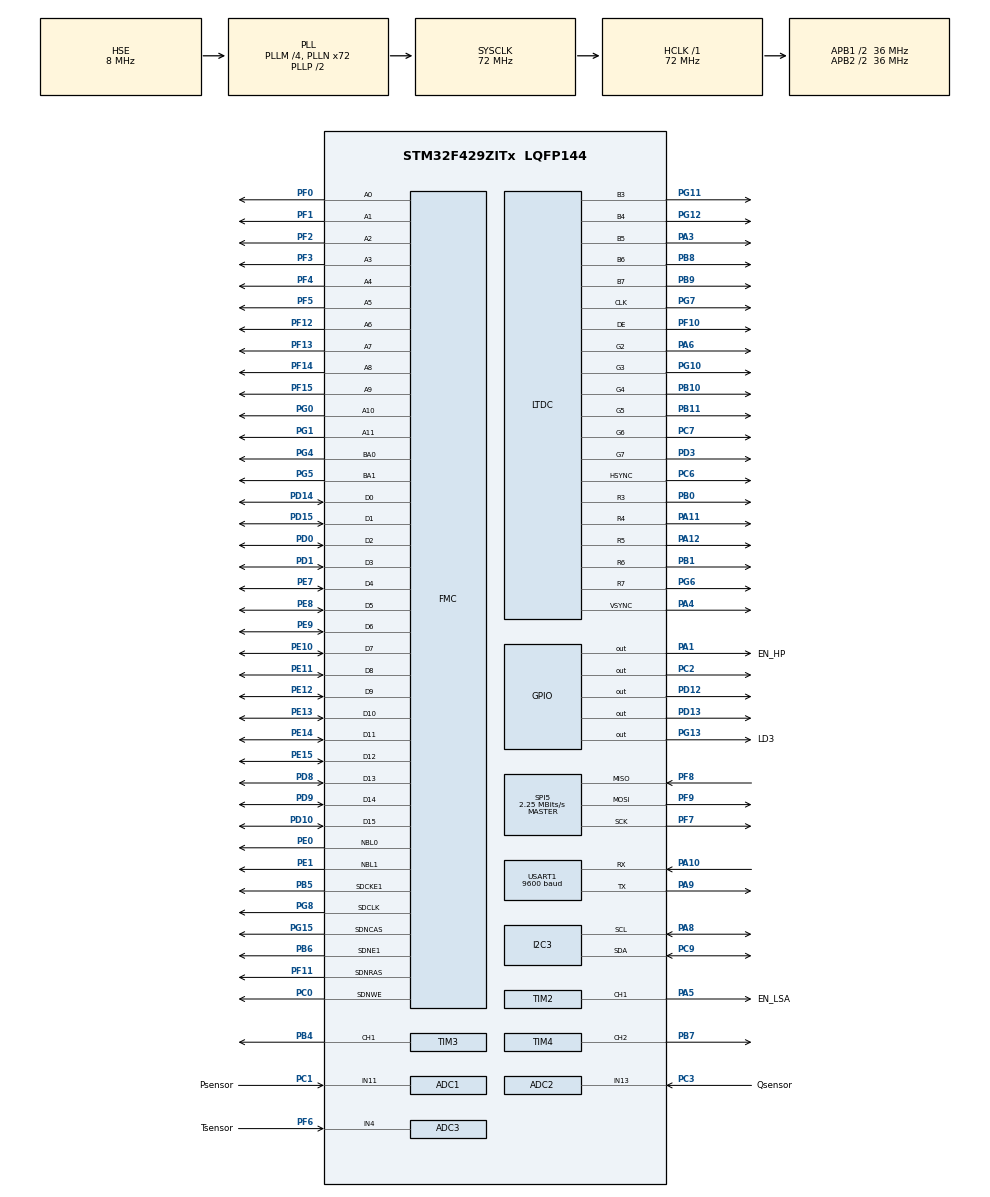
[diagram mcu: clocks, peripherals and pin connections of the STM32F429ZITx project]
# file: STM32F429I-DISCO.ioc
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ADC1.Channel-0\#ChannelRegularConversion=ADC_CHANNEL_11
ADC1.DMAContinuousRequests=ENABLE
ADC1.ExternalTrigConv=ADC_EXTERNALTRIGCONV_T3_TRGO
ADC1.ExternalTrigConvEdge=ADC_EXTERNALTRIGCONVEDGE_RISINGFALLING
ADC1.NbrOfConversionFlag=1
ADC1.Rank-0\#ChannelRegularConversion=1
ADC1.SamplingTime-0\#ChannelRegularConversion=ADC_SAMPLETIME_3CYCLES
ADC1.master=1
ADC2.Channel-0\#ChannelRegularConversion=ADC_CHANNEL_13
ADC2.DMAContinuousRequests=ENABLE
ADC2.ExternalTrigConv=ADC_EXTERNALTRIGCONV_T3_TRGO
ADC2.ExternalTrigConvEdge=ADC_EXTERNALTRIGCONVEDGE_RISINGFALLING
ADC2.NbrOfConversionFlag=1
ADC2.Rank-0\#ChannelRegularConversion=1
ADC2.SamplingTime-0\#ChannelRegularConversion=ADC_SAMPLETIME_3CYCLES
ADC3.Channel-0\#ChannelRegularConversion=ADC_CHANNEL_4
ADC3.ContinuousConvMode=ENABLE
ADC3.ExternalTrigConv=ADC_EXTERNALTRIGCONV_T3_TRGO
ADC3.ExternalTrigConvEdge=ADC_EXTERNALTRIGCONVEDGE_RISINGFALLING
ADC3.NbrOfConversionFlag=1
ADC3.Rank-0\#ChannelRegularConversion=1
ADC3.SamplingTime-0\#ChannelRegularConversion=ADC_SAMPLETIME_3CYCLES
DMA2D.ColorMode=DMA2D_OUTPUT_RGB565
Dma.ADC1.0.Direction=DMA_PERIPH_TO_MEMORY
Dma.ADC1.0.FIFOMode=DMA_FIFOMODE_DISABLE
Dma.ADC1.0.Instance=DMA2_Stream0
Dma.ADC1.0.MemDataAlignment=DMA_MDATAALIGN_HALFWORD
Dma.ADC1.0.MemInc=DMA_MINC_ENABLE
Dma.ADC1.0.Mode=DMA_CIRCULAR
Dma.ADC1.0.PeriphDataAlignment=DMA_PDATAALIGN_HALFWORD
Dma.ADC1.0.PeriphInc=DMA_PINC_DISABLE
Dma.ADC1.0.Priority=DMA_PRIORITY_LOW
Dma.ADC2.1.Direction=DMA_PERIPH_TO_MEMORY
Dma.ADC2.1.FIFOMode=DMA_FIFOMODE_DISABLE
Dma.ADC2.1.Instance=DMA2_Stream2
Dma.ADC2.1.MemDataAlignment=DMA_MDATAALIGN_HALFWORD
Dma.ADC2.1.MemInc=DMA_MINC_ENABLE
Dma.ADC2.1.Mode=DMA_CIRCULAR
Dma.ADC2.1.PeriphDataAlignment=DMA_PDATAALIGN_HALFWORD
Dma.ADC2.1.PeriphInc=DMA_PINC_DISABLE
Dma.ADC2.1.Priority=DMA_PRIORITY_LOW
Dma.Request0=ADC1
Dma.Request1=ADC2
Dma.Request2=USART1_TX
Dma.USART1_TX.2.Direction=DMA_MEMORY_TO_PERIPH
Dma.USART1_TX.2.FIFOMode=DMA_FIFOMODE_DISABLE
Dma.USART1_TX.2.Instance=DMA2_Stream7
Dma.USART1_TX.2.MemDataAlignment=DMA_MDATAALIGN_BYTE
Dma.USART1_TX.2.MemInc=DMA_MINC_ENABLE
Dma.USART1_TX.2.Mode=DMA_NORMAL
Dma.USART1_TX.2.PeriphDataAlignment=DMA_PDATAALIGN_BYTE
Dma.USART1_TX.2.PeriphInc=DMA_PINC_DISABLE
Dma.USART1_TX.2.Priority=DMA_PRIORITY_LOW
FMC.CASLatency1=FMC_SDRAM_CAS_LATENCY_3
FMC.ExitSelfRefreshDelay1=7
FMC.LoadToActiveDelay1=2
FMC.RCDDelay1=2
FMC.RPDelay1=2
FMC.ReadPipeDelay1=FMC_SDRAM_RPIPE_DELAY_1
FMC.RowCycleDelay1=7
FMC.SDClockPeriod1=FMC_SDRAM_CLOCK_PERIOD_2
FMC.SelfRefreshTime1=4
FMC.WriteRecoveryTime1=3
FREERTOS.Queues01=ADCstate,8,int,0,Dynamic,NULL,NULL;CallMeasurement,8,int,0,Dynamic,NULL,NULL;ProgressBar,8,int,0,Dynamic,NULL,NULL;SaveDataCheck,8,int,0,Dynamic,NULL,NULL;SaveDataEnd,8,int,0,Dynamic,NULL,NULL
FREERTOS.Tasks01=GUI_Task,32,4096,TouchGFX_Task,As weak,NULL,Dynamic,NULL,NULL;PQReader,24,4096,ImpedanceCalculator,Default,NULL,Dynamic,NULL,NULL;TemperatureCont,24,256,TempControl,Default,NULL,Dynamic,NULL,NULL;Accuator,24,256,StartActuating,Default,NULL,Dynamic,NULL,NULL;SaveDataFromBLE,24,2048,SaveData,Default,NULL,Dynamic,NULL,NULL
FREERTOS.configMAX_PRIORITIES=56
FREERTOS.configTOTAL_HEAP_SIZE=65536
FREERTOS.configUSE_APPLICATION_TASK_TAG=1
FREERTOS.configUSE_NEWLIB_REENTRANT=1
I2C3.Analog_Filter=I2C_ANALOGFILTER_DISABLE
LTDC.ActiveH=320
LTDC.ActiveW=240
LTDC.Alpha_L0=255
LTDC.BlendingFactor1_L0=LTDC_BLENDING_FACTOR1_CA
LTDC.BlendingFactor2_L0=LTDC_BLENDING_FACTOR2_CA
LTDC.Blue_L0=0
LTDC.HBP=20
LTDC.HFP=10
LTDC.HSync=10
LTDC.ImageHeight_L0=320
LTDC.ImageWidth_L0=240
LTDC.Layers=0
LTDC.PixelFormat_L0=LTDC_PIXEL_FORMAT_RGB565
LTDC.VFP=4
LTDC.VSync=2
LTDC.WindowX1_L0=240
LTDC.WindowY1_L0=320
Mcu.Family=STM32F4
Mcu.Name=STM32F429ZITx
Mcu.Package=LQFP144
NVIC.DMA2D_IRQn=true\:5\:0\:true\:false\:true\:true\:true\:true\:true
NVIC.DMA2_Stream0_IRQn=true\:5\:0\:false\:false\:true\:true\:false\:true\:true
NVIC.DMA2_Stream2_IRQn=true\:5\:0\:false\:false\:true\:true\:false\:true\:true
NVIC.DMA2_Stream7_IRQn=true\:5\:0\:false\:false\:true\:true\:false\:true\:true
NVIC.LTDC_IRQn=true\:5\:0\:true\:false\:true\:true\:true\:true\:true
NVIC.PriorityGroup=NVIC_PRIORITYGROUP_4
NVIC.TIM6_DAC_IRQn=true\:0\:0\:false\:false\:true\:false\:false\:true\:true
NVIC.TimeBase=TIM6_DAC_IRQn
NVIC.TimeBaseIP=TIM6
NVIC.USART1_IRQn=true\:5\:0\:false\:false\:true\:true\:true\:true\:true
PA1.GPIO_Label=EN_HP
PA1.Signal=GPIO_Output
PA10.Mode=Asynchronous
PA10.Signal=USART1_RX
PA11.GPIO_Speed=GPIO_SPEED_FREQ_HIGH
PA11.Mode=RGB565
PA11.Signal=LTDC_R4
PA12.GPIO_Speed=GPIO_SPEED_FREQ_HIGH
PA12.Mode=RGB565
PA12.Signal=LTDC_R5
PA13.Mode=Serial_Wire
PA13.Signal=SYS_JTMS-SWDIO
PA14.Mode=Serial_Wire
PA14.Signal=SYS_JTCK-SWCLK
PA3.GPIO_Speed=GPIO_SPEED_FREQ_HIGH
PA3.Mode=RGB565
PA3.Signal=LTDC_B5
PA4.GPIO_Speed=GPIO_SPEED_FREQ_HIGH
PA4.Mode=RGB565
PA4.Signal=LTDC_VSYNC
PA5.GPIO_Label=EN_LSA
PA5.GPIO_PuPd=GPIO_NOPULL
PA5.Signal=S_TIM2_CH1_ETR
PA6.GPIO_Speed=GPIO_SPEED_FREQ_HIGH
PA6.Mode=RGB565
PA6.Signal=LTDC_G2
PA8.Mode=I2C
PA8.Signal=I2C3_SCL
PA9.GPIO_PuPd=GPIO_PULLUP
PA9.Mode=Asynchronous
PA9.Signal=USART1_TX
PB0.GPIO_Speed=GPIO_SPEED_FREQ_HIGH
PB0.Mode=RGB565
PB0.Signal=LTDC_R3
PB1.GPIO_Speed=GPIO_SPEED_FREQ_HIGH
PB1.Mode=RGB565
PB1.Signal=LTDC_R6
PB10.GPIO_Speed=GPIO_SPEED_FREQ_HIGH
PB10.Mode=RGB565
PB10.Signal=LTDC_G4
PB11.GPIO_Speed=GPIO_SPEED_FREQ_HIGH
PB11.Mode=RGB565
PB11.Signal=LTDC_G5
PB4.Signal=S_TIM3_CH1
PB5.Mode=SdramChipSelect2_1
PB5.Signal=FMC_SDCKE1
PB6.Mode=SdramChipSelect2_1
PB6.Signal=FMC_SDNE1
PB7.Signal=S_TIM4_CH2
PB8.GPIO_Speed=GPIO_SPEED_FREQ_HIGH
PB8.Mode=RGB565
PB8.Signal=LTDC_B6
PB9.GPIO_Speed=GPIO_SPEED_FREQ_HIGH
PB9.Mode=RGB565
PB9.Signal=LTDC_B7
PC0.Signal=FMC_SDNWE
PC1.GPIO_Label=Psensor
PC1.Signal=ADCx_IN11
PC2.GPIO_Speed=GPIO_SPEED_FREQ_HIGH
PC2.Signal=GPIO_Output
PC3.GPIO_Label=Qsensor
PC3.Signal=ADCx_IN13
PC6.GPIO_Speed=GPIO_SPEED_FREQ_HIGH
PC6.Mode=RGB565
PC6.Signal=LTDC_HSYNC
PC7.GPIO_Speed=GPIO_SPEED_FREQ_HIGH
PC7.Mode=RGB565
PC7.Signal=LTDC_G6
PC9.Mode=I2C
PC9.Signal=I2C3_SDA
PD0.Signal=FMC_D2_DA2
PD1.Signal=FMC_D3_DA3
PD10.Signal=FMC_D15_DA15
PD12.GPIO_Speed=GPIO_SPEED_FREQ_HIGH
PD12.Signal=GPIO_Output
PD13.GPIO_Speed=GPIO_SPEED_FREQ_HIGH
PD13.Signal=GPIO_Output
PD14.Signal=FMC_D0_DA0
PD15.Signal=FMC_D1_DA1
PD3.GPIO_Speed=GPIO_SPEED_FREQ_HIGH
PD3.Mode=RGB565
PD3.Signal=LTDC_G7
PD8.Signal=FMC_D13_DA13
PD9.Signal=FMC_D14_DA14
PE0.Signal=FMC_NBL0
PE1.Signal=FMC_NBL1
PE10.Signal=FMC_D7_DA7
PE11.Signal=FMC_D8_DA8
PE12.Signal=FMC_D9_DA9
PE13.Signal=FMC_D10_DA10
PE14.Signal=FMC_D11_DA11
PE15.Signal=FMC_D12_DA12
PE7.Signal=FMC_D4_DA4
PE8.Signal=FMC_D5_DA5
PE9.Signal=FMC_D6_DA6
PF0.Signal=FMC_A0
PF1.Signal=FMC_A1
PF10.GPIO_Speed=GPIO_SPEED_FREQ_HIGH
PF10.Mode=RGB565
PF10.Signal=LTDC_DE
PF11.Signal=FMC_SDNRAS
PF12.Signal=FMC_A6
PF13.Signal=FMC_A7
PF14.Signal=FMC_A8
PF15.Signal=FMC_A9
PF2.Signal=FMC_A2
PF3.Signal=FMC_A3
PF4.Signal=FMC_A4
PF5.Signal=FMC_A5
PF6.GPIO_Label=Tsensor
PF6.Mode=IN4
PF6.Signal=ADC3_IN4
PF7.Mode=Full_Duplex_Master
PF7.Signal=SPI5_SCK
PF8.Mode=Full_Duplex_Master
PF8.Signal=SPI5_MISO
PF9.Mode=Full_Duplex_Master
PF9.Signal=SPI5_MOSI
PG0.Signal=FMC_A10
PG1.Signal=FMC_A11
PG10.GPIO_Speed=GPIO_SPEED_FREQ_HIGH
PG10.Mode=RGB565
PG10.Signal=LTDC_G3
PG11.GPIO_Speed=GPIO_SPEED_FREQ_HIGH
PG11.Mode=RGB565
PG11.Signal=LTDC_B3
PG12.GPIO_Speed=GPIO_SPEED_FREQ_HIGH
PG12.Mode=RGB565
PG12.Signal=LTDC_B4
PG13.GPIO_Label=LD3
PG13.Signal=GPIO_Output
PG15.Signal=FMC_SDNCAS
PG4.Signal=FMC_A14_BA0
PG5.Signal=FMC_A15_BA1
PG6.GPIO_Speed=GPIO_SPEED_FREQ_HIGH
PG6.Mode=RGB565
PG6.Signal=LTDC_R7
PG7.GPIO_Speed=GPIO_SPEED_FREQ_HIGH
PG7.Mode=RGB565
PG7.Signal=LTDC_CLK
PG8.Signal=FMC_SDCLK
PH0/OSC_IN.Mode=HSE-External-Oscillator
PH0/OSC_IN.Signal=RCC_OSC_IN
PH1/OSC_OUT.Mode=HSE-External-Oscillator
PH1/OSC_OUT.Signal=RCC_OSC_OUT
ProjectManager.HeapSize=0xA00
ProjectManager.StackSize=0xA00
ProjectManager.TargetToolchain=STM32CubeIDE
RCC.48MHZClocksFreq_Value=48000000
RCC.AHBFreq_Value=72000000
RCC.APB1CLKDivider=RCC_HCLK_DIV2
RCC.APB1Freq_Value=36000000
RCC.APB1TimFreq_Value=72000000
RCC.APB2CLKDivider=RCC_HCLK_DIV2
RCC.APB2Freq_Value=36000000
RCC.APB2TimFreq_Value=72000000
RCC.CortexFreq_Value=72000000
RCC.HCLKFreq_Value=72000000
RCC.HSE_VALUE=8000000
RCC.HSI_VALUE=16000000
RCC.LSE_VALUE=32768
RCC.PLLM=4
RCC.PLLN=72
RCC.PLLQ=3
RCC.PLLSAIDivR=RCC_PLLSAIDIVR_4
RCC.PLLSAIN=60
RCC.PLLSAIR=5
RCC.PLLSourceVirtual=RCC_PLLSOURCE_HSE
RCC.SYSCLKFreq_VALUE=72000000
RCC.SYSCLKSource=RCC_SYSCLKSOURCE_PLLCLK
RCC.VCOOutputFreq_Value=144000000
SH.ADCx_IN11.0=ADC1_IN11,IN11
SH.ADCx_IN13.0=ADC2_IN13,IN13
SH.FMC_A0.0=FMC_A0,12b-sda1
SH.FMC_A1.0=FMC_A1,12b-sda1
SH.FMC_A10.0=FMC_A10,12b-sda1
SH.FMC_A11.0=FMC_A11,12b-sda1
SH.FMC_A14_BA0.0=FMC_BA0,FourSdramBanks1
SH.FMC_A15_BA1.0=FMC_BA1,FourSdramBanks1
SH.FMC_A2.0=FMC_A2,12b-sda1
SH.FMC_A3.0=FMC_A3,12b-sda1
SH.FMC_A4.0=FMC_A4,12b-sda1
SH.FMC_A5.0=FMC_A5,12b-sda1
SH.FMC_A6.0=FMC_A6,12b-sda1
SH.FMC_A7.0=FMC_A7,12b-sda1
SH.FMC_A8.0=FMC_A8,12b-sda1
SH.FMC_A9.0=FMC_A9,12b-sda1
SH.FMC_D0_DA0.0=FMC_D0,sd-16b-d1
SH.FMC_D10_DA10.0=FMC_D10,sd-16b-d1
SH.FMC_D11_DA11.0=FMC_D11,sd-16b-d1
SH.FMC_D12_DA12.0=FMC_D12,sd-16b-d1
SH.FMC_D13_DA13.0=FMC_D13,sd-16b-d1
SH.FMC_D14_DA14.0=FMC_D14,sd-16b-d1
SH.FMC_D15_DA15.0=FMC_D15,sd-16b-d1
SH.FMC_D1_DA1.0=FMC_D1,sd-16b-d1
SH.FMC_D2_DA2.0=FMC_D2,sd-16b-d1
SH.FMC_D3_DA3.0=FMC_D3,sd-16b-d1
SH.FMC_D4_DA4.0=FMC_D4,sd-16b-d1
SH.FMC_D5_DA5.0=FMC_D5,sd-16b-d1
SH.FMC_D6_DA6.0=FMC_D6,sd-16b-d1
SH.FMC_D7_DA7.0=FMC_D7,sd-16b-d1
SH.FMC_D8_DA8.0=FMC_D8,sd-16b-d1
SH.FMC_D9_DA9.0=FMC_D9,sd-16b-d1
SH.FMC_NBL0.0=FMC_NBL0,Sd2ByteEnable1
SH.FMC_NBL1.0=FMC_NBL1,Sd2ByteEnable1
SH.FMC_SDCLK.0=FMC_SDCLK,12b-sda1
SH.FMC_SDNCAS.0=FMC_SDNCAS,12b-sda1
SH.FMC_SDNRAS.0=FMC_SDNRAS,12b-sda1
SH.FMC_SDNWE.0=FMC_SDNWE,12b-sda1
SH.S_TIM2_CH1_ETR.0=TIM2_CH1,PWM Generation1 CH1
SH.S_TIM3_CH1.0=TIM3_CH1,Output Compare1 CH1
SH.S_TIM4_CH2.0=TIM4_CH2,PWM Generation2 CH2
SPI5.BaudRatePrescaler=SPI_BAUDRATEPRESCALER_16
SPI5.CLKPolarity=SPI_POLARITY_LOW
SPI5.CRCCalculation=SPI_CRCCALCULATION_DISABLE
SPI5.CalculateBaudRate=2.25 MBits/s
SPI5.Direction=SPI_DIRECTION_2LINES
SPI5.Mode=SPI_MODE_MASTER
SPI5.VirtualType=VM_MASTER
STMicroelectronics.X-CUBE-TOUCHGFX.4.19.1.ApplicationCcGraphicsJjApplication=TouchGFXOoGenerator
STMicroelectronics.X-CUBE-TOUCHGFX.4.19.1.tgfx_address1=0xd0000000
STMicroelectronics.X-CUBE-TOUCHGFX.4.19.1.tgfx_buffering_strategy=Double
STMicroelectronics.X-CUBE-TOUCHGFX.4.19.1.tgfx_custom_height=240
STMicroelectronics.X-CUBE-TOUCHGFX.4.19.1.tgfx_display_interface=disp_ltdc
STMicroelectronics.X-CUBE-TOUCHGFX.4.19.1.tgfx_hardware_accelerator=dma_2d
STMicroelectronics.X-CUBE-TOUCHGFX.4.19.1.tgfx_location=Allocate
STMicroelectronics.X-CUBE-TOUCHGFX.4.19.1.tgfx_vsync=vsync_ltdc
TIM2.Channel-PWM\ Generation1\ CH1=TIM_CHANNEL_1
TIM2.Period=72000
TIM2.Prescaler=1000
TIM2.Pulse-PWM\ Generation1\ CH1=72000
TIM3.AutoReloadPreload=TIM_AUTORELOAD_PRELOAD_ENABLE
TIM3.Channel-Output\ Compare1\ CH1=TIM_CHANNEL_1
TIM3.OCMode_1=TIM_OCMODE_TOGGLE
TIM3.Period=35156-1
TIM3.TIM_MasterOutputTrigger=TIM_TRGO_UPDATE
TIM4.AutoReloadPreload=TIM_AUTORELOAD_PRELOAD_DISABLE
TIM4.Channel-PWM\ Generation2\ CH2=TIM_CHANNEL_2
TIM4.Period=0
TIM4.Prescaler=1000
USART1.BaudRate=9600
USART1.VirtualMode=VM_ASYNC
VP_CRC_VS_CRC.Mode=CRC_Activate
VP_DMA2D_VS_DMA2D.Mode=DMA2D_Activate
VP_FREERTOS_VS_CMSIS_V2.Mode=CMSIS_V2
VP_STMicroelectronics.X-CUBE-TOUCHGFX_VS_GraphicsJjApplication_4.19.1.Mode=GraphicsJjApplication
VP_SYS_VS_tim6.Mode=TIM6
VP_TIM1_VS_ClockSourceINT.Mode=Internal
board=custom

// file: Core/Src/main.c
/* USER CODE BEGIN Header */
/**
  ******************************************************************************
  * @file           : main.c
  * @brief          : Main program body
  ******************************************************************************
  * @attention
  *
  * <h2><center>&copy; Copyright (c) 2020 STMicroelectronics.
  * All rights reserved.</center></h2>
  *
  * This software component is licensed by ST under Ultimate Liberty license
  * SLA0044, the "License"; You may not use this file except in compliance with
  * the License. You may obtain a copy of the License at:
  *                             www.st.com/SLA0044
  *
  ******************************************************************************
  */
/* USER CODE END Header */

#include "main.h"
#include "cmsis_os.h"
#include "app_touchgfx.h"

/* USER CODE BEGIN Includes */

#include "Components/ili9341/ili9341.h"
#define ARM_MATH_CM4
#include "math.h"
#include "arm_math.h"
#include "queue.h"
#include "FreeRTOSConfig.h"
#include "stdio.h"
/* USER CODE END Includes */

/* USER CODE BEGIN PD */
#define REFRESH_COUNT           ((uint32_t)1386)   /* SDRAM refresh counter */
#define SDRAM_TIMEOUT           ((uint32_t)0xFFFF)

#define ADC_BUF_LEN_P 2048
#define ADC_BUF_LEN_Q 2048

#define CHAR_BUFF_SIZE 8

/**
  * @brief  FMC SDRAM Mode definition register defines
  */
#define SDRAM_MODEREG_BURST_LENGTH_1             ((uint16_t)0x0000)
#define SDRAM_MODEREG_BURST_LENGTH_2             ((uint16_t)0x0001)
#define SDRAM_MODEREG_BURST_LENGTH_4             ((uint16_t)0x0002)
#define SDRAM_MODEREG_BURST_LENGTH_8             ((uint16_t)0x0004)
#define SDRAM_MODEREG_BURST_TYPE_SEQUENTIAL      ((uint16_t)0x0000)
#define SDRAM_MODEREG_BURST_TYPE_INTERLEAVED     ((uint16_t)0x0008)
#define SDRAM_MODEREG_CAS_LATENCY_2              ((uint16_t)0x0020)
#define SDRAM_MODEREG_CAS_LATENCY_3              ((uint16_t)0x0030)
#define SDRAM_MODEREG_OPERATING_MODE_STANDARD    ((uint16_t)0x0000)
#define SDRAM_MODEREG_WRITEBURST_MODE_PROGRAMMED ((uint16_t)0x0000)
#define SDRAM_MODEREG_WRITEBURST_MODE_SINGLE     ((uint16_t)0x0200)

#define I2C3_TIMEOUT_MAX                    0x3000 /*<! The value of the maximal timeout for I2C waiting loops */
#define SPI5_TIMEOUT_MAX                    0x1000
/* USER CODE END PD */

ADC_HandleTypeDef hadc1;
ADC_HandleTypeDef hadc2;
ADC_HandleTypeDef hadc3;
DMA_HandleTypeDef hdma_adc1;
DMA_HandleTypeDef hdma_adc2;

CRC_HandleTypeDef hcrc;

DMA2D_HandleTypeDef hdma2d;

I2C_HandleTypeDef hi2c3;

LTDC_HandleTypeDef hltdc;

SPI_HandleTypeDef hspi5;

TIM_HandleTypeDef htim1;
TIM_HandleTypeDef htim2;
TIM_HandleTypeDef htim3;
TIM_HandleTypeDef htim4;

UART_HandleTypeDef huart1;
DMA_HandleTypeDef hdma_usart1_tx;

SDRAM_HandleTypeDef hsdram1;

/* Definitions for GUI_Task */
osThreadId_t GUI_TaskHandle;
const osThreadAttr_t GUI_Task_attributes = {
  .name = "GUI_Task",
  .priority = (osPriority_t) osPriorityAboveNormal,
  .stack_size = 4096 * 4
};
/* Definitions for PQReader */
osThreadId_t PQReaderHandle;
const osThreadAttr_t PQReader_attributes = {
  .name = "PQReader",
  .priority = (osPriority_t) osPriorityNormal,
  .stack_size = 4096 * 4
};
/* Definitions for TemperatureCont */
osThreadId_t TemperatureContHandle;
const osThreadAttr_t TemperatureCont_attributes = {
  .name = "TemperatureCont",
  .priority = (osPriority_t) osPriorityNormal,
  .stack_size = 256 * 4
};
/* Definitions for Accuator */
osThreadId_t AccuatorHandle;
const osThreadAttr_t Accuator_attributes = {
  .name = "Accuator",
  .priority = (osPriority_t) osPriorityNormal,
  .stack_size = 256 * 4
};
/* Definitions for SaveDataFromBLE */
osThreadId_t SaveDataFromBLEHandle;
const osThreadAttr_t SaveDataFromBLE_attributes = {
  .name = "SaveDataFromBLE",
  .priority = (osPriority_t) osPriorityNormal,
  .stack_size = 2048 * 4
};
/* Definitions for ADCstate */
osMessageQueueId_t ADCstateHandle;
const osMessageQueueAttr_t ADCstate_attributes = {
  .name = "ADCstate"
};
/* Definitions for CallMeasurement */
osMessageQueueId_t CallMeasurementHandle;
const osMessageQueueAttr_t CallMeasurement_attributes = {
  .name = "CallMeasurement"
};
/* Definitions for ProgressBar */
osMessageQueueId_t ProgressBarHandle;
const osMessageQueueAttr_t ProgressBar_attributes = {
  .name = "ProgressBar"
};
/* Definitions for SaveDataCheck */
osMessageQueueId_t SaveDataCheckHandle;
const osMessageQueueAttr_t SaveDataCheck_attributes = {
  .name = "SaveDataCheck"
};
/* Definitions for SaveDataEnd */
osMessageQueueId_t SaveDataEndHandle;
const osMessageQueueAttr_t SaveDataEnd_attributes = {
  .name = "SaveDataEnd"
};
/* USER CODE BEGIN PV */

//ADC+FFT
arm_rfft_fast_instance_f32 fft_handler;

uint16_t adc_buf_p[ADC_BUF_LEN_P];
uint16_t adc_buf_q[ADC_BUF_LEN_Q];
float32_t fftin_buf_p[ADC_BUF_LEN_P];
float32_t fftin_buf_q[ADC_BUF_LEN_P];
float32_t out_buf_p[ADC_BUF_LEN_P];
float32_t out_buf_q[ADC_BUF_LEN_Q];

int Freq=5;

int NewBuffState;
int PowerState=0;
//impedance array
float Resistance[31];
float Reactance [31];

//Frequency sweeping variable
float pres;
int FreqSweep=5;
float FreqSweepConverter;
float Duty50;

//Temperature control variable
uint16_t Temp_Vdigital;
float Temp_Vanalogue;
float Temp;

/* USER CODE END PV */

void SystemClock_Config(void);
static void MX_GPIO_Init(void);
static void MX_CRC_Init(void);
static void MX_I2C3_Init(void);
static void MX_SPI5_Init(void);
static void MX_FMC_Init(void);
static void MX_LTDC_Init(void);
static void MX_DMA2D_Init(void);
static void MX_TIM3_Init(void);
static void MX_ADC3_Init(void);
static void MX_DMA_Init(void);
static void MX_ADC1_Init(void);
static void MX_ADC2_Init(void);
static void MX_TIM1_Init(void);
static void MX_TIM4_Init(void);
static void MX_USART1_UART_Init(void);
static void MX_TIM2_Init(void);
void TouchGFX_Task(void *argument);
void ImpedanceCalculator(void *argument);
void TempControl(void *argument);
void StartActuating(void *argument);
void SaveData(void *argument);

/* USER CODE BEGIN PFP */
static void BSP_SDRAM_Initialization_Sequence(SDRAM_HandleTypeDef *hsdram, FMC_SDRAM_CommandTypeDef *Command);

static uint8_t            I2C3_ReadData(uint8_t Addr, uint8_t Reg);
static void               I2C3_WriteData(uint8_t Addr, uint8_t Reg, uint8_t Value);
static uint8_t            I2C3_ReadBuffer(uint8_t Addr, uint8_t Reg, uint8_t *pBuffer, uint16_t Length);

/* SPIx bus function */
static void               SPI5_Write(uint16_t Value);
static uint32_t           SPI5_Read(uint8_t ReadSize);
static void               SPI5_Error(void);

/* Link function for LCD peripheral */
void                      LCD_IO_Init(void);
void                      LCD_IO_WriteData(uint16_t RegValue);
void                      LCD_IO_WriteReg(uint8_t Reg);
uint32_t                  LCD_IO_ReadData(uint16_t RegValue, uint8_t ReadSize);
void                      LCD_Delay(uint32_t delay);

/* IOExpander IO functions */
void                      IOE_Init(void);
void                      IOE_ITConfig(void);
void                      IOE_Delay(uint32_t Delay);
void                      IOE_Write(uint8_t Addr, uint8_t Reg, uint8_t Value);
uint8_t                   IOE_Read(uint8_t Addr, uint8_t Reg);
uint16_t                  IOE_ReadMultiple(uint8_t Addr, uint8_t Reg, uint8_t *pBuffer, uint16_t Length);

/*fft computation*/
float32_t complexDiv_R(float32_t R1,float32_t I1,float32_t R2,float32_t I2);
float32_t complexDiv_X(float32_t R1,float32_t I1,float32_t R2,float32_t I2);
void DoFFT(int frequency);

/* USER CODE END PFP */

/* USER CODE BEGIN 0 */
static LCD_DrvTypeDef* LcdDrv;

uint32_t I2c3Timeout = I2C3_TIMEOUT_MAX; /*<! Value of Timeout when I2C communication fails */
uint32_t Spi5Timeout = SPI5_TIMEOUT_MAX; /*<! Value of Timeout when SPI communication fails */

/* USER CODE END 0 */

int main(void)
{

  /* MCU Configuration--------------------------------------------------------*/

  /* Reset of all peripherals, Initializes the Flash interface and the Systick. */
  HAL_Init();

  /* Configure the system clock */
  SystemClock_Config();

  /* Initialize all configured peripherals */
  MX_GPIO_Init();
  MX_CRC_Init();
  MX_I2C3_Init();
  MX_SPI5_Init();
  MX_FMC_Init();
  MX_LTDC_Init();
  MX_DMA2D_Init();
  MX_TIM3_Init();
  MX_ADC3_Init();
  MX_DMA_Init();
  MX_ADC1_Init();
  MX_ADC2_Init();
  MX_TIM1_Init();
  MX_TIM4_Init();
  MX_USART1_UART_Init();
  MX_TIM2_Init();
  MX_TouchGFX_Init();
  /* USER CODE BEGIN 2 */

//  TIM2->CCR1 = TIM2->ARR + 1;
  arm_rfft_fast_init_f32(&fft_handler, 2048);

  //---------------ADC function---------------------------//
  //Set AAR=17578*2, ADC SAMPLE frequency at 2.048kHz
  HAL_TIM_Base_Start(&htim3);
  HAL_TIM_OC_Start(&htim3, TIM_CHANNEL_1);//debug line PB4
  //initiate ADC transfer to DMA, clocked by the compare register.

  HAL_TIM_PWM_Start( &htim2, TIM_CHANNEL_1 );
  HAL_TIM_OC_Start(&htim2, TIM_CHANNEL_1);
  htim2.Instance->ARR=72000;
  htim2.Instance->CCR1=htim2.Instance->ARR +1;
  /* USER CODE END 2 */

  /* Init scheduler */
  osKernelInitialize();

  /* Create the queue(s) */
  /* creation of ADCstate */
  ADCstateHandle = osMessageQueueNew (8, sizeof(int), &ADCstate_attributes);

  /* creation of CallMeasurement */
  CallMeasurementHandle = osMessageQueueNew (8, sizeof(int), &CallMeasurement_attributes);

  /* creation of ProgressBar */
  ProgressBarHandle = osMessageQueueNew (8, sizeof(int), &ProgressBar_attributes);

  /* creation of SaveDataCheck */
  SaveDataCheckHandle = osMessageQueueNew (8, sizeof(int), &SaveDataCheck_attributes);

  /* creation of SaveDataEnd */
  SaveDataEndHandle = osMessageQueueNew (8, sizeof(int), &SaveDataEnd_attributes);

  /* Create the thread(s) */
  /* creation of GUI_Task */
  GUI_TaskHandle = osThreadNew(TouchGFX_Task, NULL, &GUI_Task_attributes);

  /* creation of PQReader */
  PQReaderHandle = osThreadNew(ImpedanceCalculator, NULL, &PQReader_attributes);

  /* creation of TemperatureCont */
  TemperatureContHandle = osThreadNew(TempControl, NULL, &TemperatureCont_attributes);

  /* creation of Accuator */
  AccuatorHandle = osThreadNew(StartActuating, NULL, &Accuator_attributes);

  /* creation of SaveDataFromBLE */
  SaveDataFromBLEHandle = osThreadNew(SaveData, NULL, &SaveDataFromBLE_attributes);

  /* Start scheduler */
  osKernelStart();

  /* We should never get here as control is now taken by the scheduler */
  /* Infinite loop */
  while (1)
  {

  }
}

void SystemClock_Config(void)
{
  RCC_OscInitTypeDef RCC_OscInitStruct = {0};
  RCC_ClkInitTypeDef RCC_ClkInitStruct = {0};
  RCC_PeriphCLKInitTypeDef PeriphClkInitStruct = {0};

  /** Configure the main internal regulator output voltage
  */
  __HAL_RCC_PWR_CLK_ENABLE();
  __HAL_PWR_VOLTAGESCALING_CONFIG(PWR_REGULATOR_VOLTAGE_SCALE3);
  /** Initializes the CPU, AHB and APB busses clocks
  */
  RCC_OscInitStruct.OscillatorType = RCC_OSCILLATORTYPE_HSE;
  RCC_OscInitStruct.HSEState = RCC_HSE_ON;
  RCC_OscInitStruct.PLL.PLLState = RCC_PLL_ON;
  RCC_OscInitStruct.PLL.PLLSource = RCC_PLLSOURCE_HSE;
  RCC_OscInitStruct.PLL.PLLM = 4;
  RCC_OscInitStruct.PLL.PLLN = 72;
  RCC_OscInitStruct.PLL.PLLP = RCC_PLLP_DIV2;
  RCC_OscInitStruct.PLL.PLLQ = 3;
  if (HAL_RCC_OscConfig(&RCC_OscInitStruct) != HAL_OK)
  {
    Error_Handler();
  }
  /** Initializes the CPU, AHB and APB busses clocks
  */
  RCC_ClkInitStruct.ClockType = RCC_CLOCKTYPE_HCLK|RCC_CLOCKTYPE_SYSCLK
                              |RCC_CLOCKTYPE_PCLK1|RCC_CLOCKTYPE_PCLK2;
  RCC_ClkInitStruct.SYSCLKSource = RCC_SYSCLKSOURCE_PLLCLK;
  RCC_ClkInitStruct.AHBCLKDivider = RCC_SYSCLK_DIV1;
  RCC_ClkInitStruct.APB1CLKDivider = RCC_HCLK_DIV2;
  RCC_ClkInitStruct.APB2CLKDivider = RCC_HCLK_DIV2;

  if (HAL_RCC_ClockConfig(&RCC_ClkInitStruct, FLASH_LATENCY_2) != HAL_OK)
  {
    Error_Handler();
  }
  PeriphClkInitStruct.PeriphClockSelection = RCC_PERIPHCLK_LTDC;
  PeriphClkInitStruct.PLLSAI.PLLSAIN = 60;
  PeriphClkInitStruct.PLLSAI.PLLSAIR = 5;
  PeriphClkInitStruct.PLLSAIDivR = RCC_PLLSAIDIVR_4;
  if (HAL_RCCEx_PeriphCLKConfig(&PeriphClkInitStruct) != HAL_OK)
  {
    Error_Handler();
  }
}

static void MX_ADC1_Init(void)
{

  ADC_ChannelConfTypeDef sConfig = {0};

  /** Configure the global features of the ADC (Clock, Resolution, Data Alignment and number of conversion)
  */
  hadc1.Instance = ADC1;
  hadc1.Init.ClockPrescaler = ADC_CLOCK_SYNC_PCLK_DIV2;
  hadc1.Init.Resolution = ADC_RESOLUTION_12B;
  hadc1.Init.ScanConvMode = DISABLE;
  hadc1.Init.ContinuousConvMode = DISABLE;
  hadc1.Init.DiscontinuousConvMode = DISABLE;
  hadc1.Init.ExternalTrigConvEdge = ADC_EXTERNALTRIGCONVEDGE_RISINGFALLING;
  hadc1.Init.ExternalTrigConv = ADC_EXTERNALTRIGCONV_T3_TRGO;
  hadc1.Init.DataAlign = ADC_DATAALIGN_RIGHT;
  hadc1.Init.NbrOfConversion = 1;
  hadc1.Init.DMAContinuousRequests = ENABLE;
  hadc1.Init.EOCSelection = ADC_EOC_SINGLE_CONV;
  if (HAL_ADC_Init(&hadc1) != HAL_OK)
  {
    Error_Handler();
  }
  /** Configure for the selected ADC regular channel its corresponding rank in the sequencer and its sample time.
  */
  sConfig.Channel = ADC_CHANNEL_11;
  sConfig.Rank = 1;
  sConfig.SamplingTime = ADC_SAMPLETIME_3CYCLES;
  if (HAL_ADC_ConfigChannel(&hadc1, &sConfig) != HAL_OK)
  {
    Error_Handler();
  }

}

static void MX_ADC2_Init(void)
{

  ADC_ChannelConfTypeDef sConfig = {0};

  /** Configure the global features of the ADC (Clock, Resolution, Data Alignment and number of conversion)
  */
  hadc2.Instance = ADC2;
  hadc2.Init.ClockPrescaler = ADC_CLOCK_SYNC_PCLK_DIV2;
  hadc2.Init.Resolution = ADC_RESOLUTION_12B;
  hadc2.Init.ScanConvMode = DISABLE;
  hadc2.Init.ContinuousConvMode = DISABLE;
  hadc2.Init.DiscontinuousConvMode = DISABLE;
  hadc2.Init.ExternalTrigConvEdge = ADC_EXTERNALTRIGCONVEDGE_RISINGFALLING;
  hadc2.Init.ExternalTrigConv = ADC_EXTERNALTRIGCONV_T3_TRGO;
  hadc2.Init.DataAlign = ADC_DATAALIGN_RIGHT;
  hadc2.Init.NbrOfConversion = 1;
  hadc2.Init.DMAContinuousRequests = ENABLE;
  hadc2.Init.EOCSelection = ADC_EOC_SINGLE_CONV;
  if (HAL_ADC_Init(&hadc2) != HAL_OK)
  {
    Error_Handler();
  }
  /** Configure for the selected ADC regular channel its corresponding rank in the sequencer and its sample time.
  */
  sConfig.Channel = ADC_CHANNEL_13;
  sConfig.Rank = 1;
  sConfig.SamplingTime = ADC_SAMPLETIME_3CYCLES;
  if (HAL_ADC_ConfigChannel(&hadc2, &sConfig) != HAL_OK)
  {
    Error_Handler();
  }

}

static void MX_ADC3_Init(void)
{

  ADC_ChannelConfTypeDef sConfig = {0};

  /** Configure the global features of the ADC (Clock, Resolution, Data Alignment and number of conversion)
  */
  hadc3.Instance = ADC3;
  hadc3.Init.ClockPrescaler = ADC_CLOCK_SYNC_PCLK_DIV2;
  hadc3.Init.Resolution = ADC_RESOLUTION_12B;
  hadc3.Init.ScanConvMode = DISABLE;
  hadc3.Init.ContinuousConvMode = ENABLE;
  hadc3.Init.DiscontinuousConvMode = DISABLE;
  hadc3.Init.ExternalTrigConvEdge = ADC_EXTERNALTRIGCONVEDGE_RISINGFALLING;
  hadc3.Init.ExternalTrigConv = ADC_EXTERNALTRIGCONV_T3_TRGO;
  hadc3.Init.DataAlign = ADC_DATAALIGN_RIGHT;
  hadc3.Init.NbrOfConversion = 1;
  hadc3.Init.DMAContinuousRequests = DISABLE;
  hadc3.Init.EOCSelection = ADC_EOC_SINGLE_CONV;
  if (HAL_ADC_Init(&hadc3) != HAL_OK)
  {
    Error_Handler();
  }
  /** Configure for the selected ADC regular channel its corresponding rank in the sequencer and its sample time.
  */
  sConfig.Channel = ADC_CHANNEL_4;
  sConfig.Rank = 1;
  sConfig.SamplingTime = ADC_SAMPLETIME_3CYCLES;
  if (HAL_ADC_ConfigChannel(&hadc3, &sConfig) != HAL_OK)
  {
    Error_Handler();
  }

}

static void MX_CRC_Init(void)
{

  hcrc.Instance = CRC;
  if (HAL_CRC_Init(&hcrc) != HAL_OK)
  {
    Error_Handler();
  }

}

static void MX_DMA2D_Init(void)
{

  hdma2d.Instance = DMA2D;
  hdma2d.Init.Mode = DMA2D_M2M;
  hdma2d.Init.ColorMode = DMA2D_OUTPUT_RGB565;
  hdma2d.Init.OutputOffset = 0;
  hdma2d.LayerCfg[1].InputOffset = 0;
  hdma2d.LayerCfg[1].InputColorMode = DMA2D_INPUT_RGB565;
  hdma2d.LayerCfg[1].AlphaMode = DMA2D_NO_MODIF_ALPHA;
  hdma2d.LayerCfg[1].InputAlpha = 0;
  if (HAL_DMA2D_Init(&hdma2d) != HAL_OK)
  {
    Error_Handler();
  }
  if (HAL_DMA2D_ConfigLayer(&hdma2d, 1) != HAL_OK)
  {
    Error_Handler();
  }

}

static void MX_I2C3_Init(void)
{

  hi2c3.Instance = I2C3;
  hi2c3.Init.ClockSpeed = 100000;
  hi2c3.Init.DutyCycle = I2C_DUTYCYCLE_2;
  hi2c3.Init.OwnAddress1 = 0;
  hi2c3.Init.AddressingMode = I2C_ADDRESSINGMODE_7BIT;
  hi2c3.Init.DualAddressMode = I2C_DUALADDRESS_DISABLE;
  hi2c3.Init.OwnAddress2 = 0;
  hi2c3.Init.GeneralCallMode = I2C_GENERALCALL_DISABLE;
  hi2c3.Init.NoStretchMode = I2C_NOSTRETCH_DISABLE;
  if (HAL_I2C_Init(&hi2c3) != HAL_OK)
  {
    Error_Handler();
  }
  /** Configure Analogue filter
  */
  if (HAL_I2CEx_ConfigAnalogFilter(&hi2c3, I2C_ANALOGFILTER_DISABLE) != HAL_OK)
  {
    Error_Handler();
  }
  /** Configure Digital filter
  */
  if (HAL_I2CEx_ConfigDigitalFilter(&hi2c3, 0) != HAL_OK)
  {
    Error_Handler();
  }

}

static void MX_LTDC_Init(void)
{

  LTDC_LayerCfgTypeDef pLayerCfg = {0};

  hltdc.Instance = LTDC;
  hltdc.Init.HSPolarity = LTDC_HSPOLARITY_AL;
  hltdc.Init.VSPolarity = LTDC_VSPOLARITY_AL;
  hltdc.Init.DEPolarity = LTDC_DEPOLARITY_AL;
  hltdc.Init.PCPolarity = LTDC_PCPOLARITY_IPC;
  hltdc.Init.HorizontalSync = 9;
  hltdc.Init.VerticalSync = 1;
  hltdc.Init.AccumulatedHBP = 29;
  hltdc.Init.AccumulatedVBP = 3;
  hltdc.Init.AccumulatedActiveW = 269;
  hltdc.Init.AccumulatedActiveH = 323;
  hltdc.Init.TotalWidth = 279;
  hltdc.Init.TotalHeigh = 327;
  hltdc.Init.Backcolor.Blue = 0;
  hltdc.Init.Backcolor.Green = 0;
  hltdc.Init.Backcolor.Red = 0;
  if (HAL_LTDC_Init(&hltdc) != HAL_OK)
  {
    Error_Handler();
  }
  pLayerCfg.WindowX0 = 0;
  pLayerCfg.WindowX1 = 240;
  pLayerCfg.WindowY0 = 0;
  pLayerCfg.WindowY1 = 320;
  pLayerCfg.PixelFormat = LTDC_PIXEL_FORMAT_RGB565;
  pLayerCfg.Alpha = 255;
  pLayerCfg.Alpha0 = 0;
  pLayerCfg.BlendingFactor1 = LTDC_BLENDING_FACTOR1_CA;
  pLayerCfg.BlendingFactor2 = LTDC_BLENDING_FACTOR2_CA;
  pLayerCfg.FBStartAdress = 0;
  pLayerCfg.ImageWidth = 240;
  pLayerCfg.ImageHeight = 320;
  pLayerCfg.Backcolor.Blue = 0;
  pLayerCfg.Backcolor.Green = 0;
  pLayerCfg.Backcolor.Red = 0;
  if (HAL_LTDC_ConfigLayer(&hltdc, &pLayerCfg, 0) != HAL_OK)
  {
    Error_Handler();
  }
  /* USER CODE BEGIN LTDC_Init 2 */
    /*Select the device */
  LcdDrv = &ili9341_drv;
  /* LCD Init */
  LcdDrv->Init();

  LcdDrv->DisplayOff();
  /* USER CODE END LTDC_Init 2 */

}

static void MX_SPI5_Init(void)
{

  /* SPI5 parameter configuration*/
  hspi5.Instance = SPI5;
  hspi5.Init.Mode = SPI_MODE_MASTER;
  hspi5.Init.Direction = SPI_DIRECTION_2LINES;
  hspi5.Init.DataSize = SPI_DATASIZE_8BIT;
  hspi5.Init.CLKPolarity = SPI_POLARITY_LOW;
  hspi5.Init.CLKPhase = SPI_PHASE_1EDGE;
  hspi5.Init.NSS = SPI_NSS_SOFT;
  hspi5.Init.BaudRatePrescaler = SPI_BAUDRATEPRESCALER_16;
  hspi5.Init.FirstBit = SPI_FIRSTBIT_MSB;
  hspi5.Init.TIMode = SPI_TIMODE_DISABLE;
  hspi5.Init.CRCCalculation = SPI_CRCCALCULATION_DISABLE;
  hspi5.Init.CRCPolynomial = 10;
  if (HAL_SPI_Init(&hspi5) != HAL_OK)
  {
    Error_Handler();
  }

}

static void MX_TIM1_Init(void)
{

  TIM_ClockConfigTypeDef sClockSourceConfig = {0};
  TIM_MasterConfigTypeDef sMasterConfig = {0};

  htim1.Instance = TIM1;
  htim1.Init.Prescaler = 0;
  htim1.Init.CounterMode = TIM_COUNTERMODE_UP;
  htim1.Init.Period = 0;
  htim1.Init.ClockDivision = TIM_CLOCKDIVISION_DIV1;
  htim1.Init.RepetitionCounter = 0;
  htim1.Init.AutoReloadPreload = TIM_AUTORELOAD_PRELOAD_DISABLE;
  if (HAL_TIM_Base_Init(&htim1) != HAL_OK)
  {
    Error_Handler();
  }
  sClockSourceConfig.ClockSource = TIM_CLOCKSOURCE_INTERNAL;
  if (HAL_TIM_ConfigClockSource(&htim1, &sClockSourceConfig) != HAL_OK)
  {
    Error_Handler();
  }
  sMasterConfig.MasterOutputTrigger = TIM_TRGO_RESET;
  sMasterConfig.MasterSlaveMode = TIM_MASTERSLAVEMODE_DISABLE;
  if (HAL_TIMEx_MasterConfigSynchronization(&htim1, &sMasterConfig) != HAL_OK)
  {
    Error_Handler();
  }

}

static void MX_TIM2_Init(void)
{

  TIM_MasterConfigTypeDef sMasterConfig = {0};
  TIM_OC_InitTypeDef sConfigOC = {0};

  htim2.Instance = TIM2;
  htim2.Init.Prescaler = 1000;
  htim2.Init.CounterMode = TIM_COUNTERMODE_UP;
  htim2.Init.Period = 72000;
  htim2.Init.ClockDivision = TIM_CLOCKDIVISION_DIV1;
  htim2.Init.AutoReloadPreload = TIM_AUTORELOAD_PRELOAD_DISABLE;
  if (HAL_TIM_PWM_Init(&htim2) != HAL_OK)
  {
    Error_Handler();
  }
  sMasterConfig.MasterOutputTrigger = TIM_TRGO_RESET;
  sMasterConfig.MasterSlaveMode = TIM_MASTERSLAVEMODE_DISABLE;
  if (HAL_TIMEx_MasterConfigSynchronization(&htim2, &sMasterConfig) != HAL_OK)
  {
    Error_Handler();
  }
  sConfigOC.OCMode = TIM_OCMODE_PWM1;
  sConfigOC.Pulse = 72000;
  sConfigOC.OCPolarity = TIM_OCPOLARITY_HIGH;
  sConfigOC.OCFastMode = TIM_OCFAST_DISABLE;
  if (HAL_TIM_PWM_ConfigChannel(&htim2, &sConfigOC, TIM_CHANNEL_1) != HAL_OK)
  {
    Error_Handler();
  }
  HAL_TIM_MspPostInit(&htim2);

}

static void MX_TIM3_Init(void)
{

  TIM_MasterConfigTypeDef sMasterConfig = {0};
  TIM_OC_InitTypeDef sConfigOC = {0};

  htim3.Instance = TIM3;
  htim3.Init.Prescaler = 0;
  htim3.Init.CounterMode = TIM_COUNTERMODE_UP;
  htim3.Init.Period = 35156-1;
  htim3.Init.ClockDivision = TIM_CLOCKDIVISION_DIV1;
  htim3.Init.AutoReloadPreload = TIM_AUTORELOAD_PRELOAD_ENABLE;
  if (HAL_TIM_OC_Init(&htim3) != HAL_OK)
  {
    Error_Handler();
  }
  sMasterConfig.MasterOutputTrigger = TIM_TRGO_UPDATE;
  sMasterConfig.MasterSlaveMode = TIM_MASTERSLAVEMODE_DISABLE;
  if (HAL_TIMEx_MasterConfigSynchronization(&htim3, &sMasterConfig) != HAL_OK)
  {
    Error_Handler();
  }
  sConfigOC.OCMode = TIM_OCMODE_TOGGLE;
  sConfigOC.Pulse = 0;
  sConfigOC.OCPolarity = TIM_OCPOLARITY_HIGH;
  sConfigOC.OCFastMode = TIM_OCFAST_DISABLE;
  if (HAL_TIM_OC_ConfigChannel(&htim3, &sConfigOC, TIM_CHANNEL_1) != HAL_OK)
  {
    Error_Handler();
  }
  HAL_TIM_MspPostInit(&htim3);

}

static void MX_TIM4_Init(void)
{

  TIM_MasterConfigTypeDef sMasterConfig = {0};
  TIM_OC_InitTypeDef sConfigOC = {0};

  htim4.Instance = TIM4;
  htim4.Init.Prescaler = 1000;
  htim4.Init.CounterMode = TIM_COUNTERMODE_UP;
  htim4.Init.Period = 0;
  htim4.Init.ClockDivision = TIM_CLOCKDIVISION_DIV1;
  htim4.Init.AutoReloadPreload = TIM_AUTORELOAD_PRELOAD_DISABLE;
  if (HAL_TIM_PWM_Init(&htim4) != HAL_OK)
  {
    Error_Handler();
  }
  sMasterConfig.MasterOutputTrigger = TIM_TRGO_RESET;
  sMasterConfig.MasterSlaveMode = TIM_MASTERSLAVEMODE_DISABLE;
  if (HAL_TIMEx_MasterConfigSynchronization(&htim4, &sMasterConfig) != HAL_OK)
  {
    Error_Handler();
  }
  sConfigOC.OCMode = TIM_OCMODE_PWM1;
  sConfigOC.Pulse = 0;
  sConfigOC.OCPolarity = TIM_OCPOLARITY_HIGH;
  sConfigOC.OCFastMode = TIM_OCFAST_DISABLE;
  if (HAL_TIM_PWM_ConfigChannel(&htim4, &sConfigOC, TIM_CHANNEL_2) != HAL_OK)
  {
    Error_Handler();
  }
  HAL_TIM_MspPostInit(&htim4);

}

static void MX_USART1_UART_Init(void)
{

  huart1.Instance = USART1;
  huart1.Init.BaudRate = 9600;
  huart1.Init.WordLength = UART_WORDLENGTH_8B;
  huart1.Init.StopBits = UART_STOPBITS_1;
  huart1.Init.Parity = UART_PARITY_NONE;
  huart1.Init.Mode = UART_MODE_TX_RX;
  huart1.Init.HwFlowCtl = UART_HWCONTROL_NONE;
  huart1.Init.OverSampling = UART_OVERSAMPLING_16;
  if (HAL_UART_Init(&huart1) != HAL_OK)
  {
    Error_Handler();
  }

}

static void MX_DMA_Init(void)
{

  /* DMA controller clock enable */
  __HAL_RCC_DMA2_CLK_ENABLE();

  /* DMA interrupt init */
  /* DMA2_Stream0_IRQn interrupt configuration */
  HAL_NVIC_SetPriority(DMA2_Stream0_IRQn, 5, 0);
  HAL_NVIC_EnableIRQ(DMA2_Stream0_IRQn);
  /* DMA2_Stream2_IRQn interrupt configuration */
  HAL_NVIC_SetPriority(DMA2_Stream2_IRQn, 5, 0);
  HAL_NVIC_EnableIRQ(DMA2_Stream2_IRQn);
  /* DMA2_Stream7_IRQn interrupt configuration */
  HAL_NVIC_SetPriority(DMA2_Stream7_IRQn, 5, 0);
  HAL_NVIC_EnableIRQ(DMA2_Stream7_IRQn);

}

/* FMC initialization function */
static void MX_FMC_Init(void)
{

  FMC_SDRAM_TimingTypeDef SdramTiming = {0};

  /** Perform the SDRAM1 memory initialization sequence
  */
  hsdram1.Instance = FMC_SDRAM_DEVICE;
  /* hsdram1.Init */
  hsdram1.Init.SDBank = FMC_SDRAM_BANK2;
  hsdram1.Init.ColumnBitsNumber = FMC_SDRAM_COLUMN_BITS_NUM_8;
  hsdram1.Init.RowBitsNumber = FMC_SDRAM_ROW_BITS_NUM_12;
  hsdram1.Init.MemoryDataWidth = FMC_SDRAM_MEM_BUS_WIDTH_16;
  hsdram1.Init.InternalBankNumber = FMC_SDRAM_INTERN_BANKS_NUM_4;
  hsdram1.Init.CASLatency = FMC_SDRAM_CAS_LATENCY_3;
  hsdram1.Init.WriteProtection = FMC_SDRAM_WRITE_PROTECTION_DISABLE;
  hsdram1.Init.SDClockPeriod = FMC_SDRAM_CLOCK_PERIOD_2;
  hsdram1.Init.ReadBurst = FMC_SDRAM_RBURST_DISABLE;
  hsdram1.Init.ReadPipeDelay = FMC_SDRAM_RPIPE_DELAY_1;
  /* SdramTiming */
  SdramTiming.LoadToActiveDelay = 2;
  SdramTiming.ExitSelfRefreshDelay = 7;
  SdramTiming.SelfRefreshTime = 4;
  SdramTiming.RowCycleDelay = 7;
  SdramTiming.WriteRecoveryTime = 3;
  SdramTiming.RPDelay = 2;
  SdramTiming.RCDDelay = 2;

  if (HAL_SDRAM_Init(&hsdram1, &SdramTiming) != HAL_OK)
  {
    Error_Handler( );
  }

  /* USER CODE BEGIN FMC_Init 2 */

  FMC_SDRAM_CommandTypeDef command;

  /* Program the SDRAM external device */
  BSP_SDRAM_Initialization_Sequence(&hsdram1, &command);
  /* USER CODE END FMC_Init 2 */
}

static void MX_GPIO_Init(void)
{
  GPIO_InitTypeDef GPIO_InitStruct = {0};

  /* GPIO Ports Clock Enable */
  __HAL_RCC_GPIOF_CLK_ENABLE();
  __HAL_RCC_GPIOH_CLK_ENABLE();
  __HAL_RCC_GPIOC_CLK_ENABLE();
  __HAL_RCC_GPIOA_CLK_ENABLE();
  __HAL_RCC_GPIOB_CLK_ENABLE();
  __HAL_RCC_GPIOG_CLK_ENABLE();
  __HAL_RCC_GPIOE_CLK_ENABLE();
  __HAL_RCC_GPIOD_CLK_ENABLE();

  /*Configure GPIO pin Output Level */
  HAL_GPIO_WritePin(GPIOC, GPIO_PIN_2, GPIO_PIN_RESET);

  /*Configure GPIO pin Output Level */
  HAL_GPIO_WritePin(EN_HP_GPIO_Port, EN_HP_Pin, GPIO_PIN_RESET);

  /*Configure GPIO pin Output Level */
  HAL_GPIO_WritePin(GPIOD, GPIO_PIN_12|GPIO_PIN_13, GPIO_PIN_RESET);

  /*Configure GPIO pin Output Level */
  HAL_GPIO_WritePin(LD3_GPIO_Port, LD3_Pin, GPIO_PIN_RESET);

  /*Configure GPIO pin : PC2 */
  GPIO_InitStruct.Pin = GPIO_PIN_2;
  GPIO_InitStruct.Mode = GPIO_MODE_OUTPUT_PP;
  GPIO_InitStruct.Pull = GPIO_NOPULL;
  GPIO_InitStruct.Speed = GPIO_SPEED_FREQ_HIGH;
  HAL_GPIO_Init(GPIOC, &GPIO_InitStruct);

  /*Configure GPIO pin : EN_HP_Pin */
  GPIO_InitStruct.Pin = EN_HP_Pin;
  GPIO_InitStruct.Mode = GPIO_MODE_OUTPUT_PP;
  GPIO_InitStruct.Pull = GPIO_NOPULL;
  GPIO_InitStruct.Speed = GPIO_SPEED_FREQ_LOW;
  HAL_GPIO_Init(EN_HP_GPIO_Port, &GPIO_InitStruct);

  /*Configure GPIO pins : PD12 PD13 */
  GPIO_InitStruct.Pin = GPIO_PIN_12|GPIO_PIN_13;
  GPIO_InitStruct.Mode = GPIO_MODE_OUTPUT_PP;
  GPIO_InitStruct.Pull = GPIO_NOPULL;
  GPIO_InitStruct.Speed = GPIO_SPEED_FREQ_HIGH;
  HAL_GPIO_Init(GPIOD, &GPIO_InitStruct);

  /*Configure GPIO pin : LD3_Pin */
  GPIO_InitStruct.Pin = LD3_Pin;
  GPIO_InitStruct.Mode = GPIO_MODE_OUTPUT_PP;
  GPIO_InitStruct.Pull = GPIO_NOPULL;
  GPIO_InitStruct.Speed = GPIO_SPEED_FREQ_LOW;
  HAL_GPIO_Init(LD3_GPIO_Port, &GPIO_InitStruct);

}

/* USER CODE BEGIN 4 */
/**
  * @brief  Perform the SDRAM external memory initialization sequence
  * @param  hsdram: SDRAM handle
  * @param  Command: Pointer to SDRAM command structure
  * @retval None
  */
static void BSP_SDRAM_Initialization_Sequence(SDRAM_HandleTypeDef *hsdram, FMC_SDRAM_CommandTypeDef *Command)
{
 __IO uint32_t tmpmrd =0;

  /* Step 1:  Configure a clock configuration enable command */
  Command->CommandMode             = FMC_SDRAM_CMD_CLK_ENABLE;
  Command->CommandTarget           = FMC_SDRAM_CMD_TARGET_BANK2;
  Command->AutoRefreshNumber       = 1;
  Command->ModeRegisterDefinition  = 0;

  /* Send the command */
  HAL_SDRAM_SendCommand(hsdram, Command, SDRAM_TIMEOUT);

  /* Step 2: Insert 100 us minimum delay */
  /* Inserted delay is equal to 1 ms due to systick time base unit (ms) */
  HAL_Delay(1);

  /* Step 3: Configure a PALL (precharge all) command */
  Command->CommandMode             = FMC_SDRAM_CMD_PALL;
  Command->CommandTarget           = FMC_SDRAM_CMD_TARGET_BANK2;
  Command->AutoRefreshNumber       = 1;
  Command->ModeRegisterDefinition  = 0;

  /* Send the command */
  HAL_SDRAM_SendCommand(hsdram, Command, SDRAM_TIMEOUT);

  /* Step 4: Configure an Auto Refresh command */
  Command->CommandMode             = FMC_SDRAM_CMD_AUTOREFRESH_MODE;
  Command->CommandTarget           = FMC_SDRAM_CMD_TARGET_BANK2;
  Command->AutoRefreshNumber       = 4;
  Command->ModeRegisterDefinition  = 0;

  /* Send the command */
  HAL_SDRAM_SendCommand(hsdram, Command, SDRAM_TIMEOUT);

  /* Step 5: Program the external memory mode register */
  tmpmrd = (uint32_t)SDRAM_MODEREG_BURST_LENGTH_1          |
                     SDRAM_MODEREG_BURST_TYPE_SEQUENTIAL   |
                     SDRAM_MODEREG_CAS_LATENCY_3           |
                     SDRAM_MODEREG_OPERATING_MODE_STANDARD |
                     SDRAM_MODEREG_WRITEBURST_MODE_SINGLE;

  Command->CommandMode             = FMC_SDRAM_CMD_LOAD_MODE;
  Command->CommandTarget           = FMC_SDRAM_CMD_TARGET_BANK2;
  Command->AutoRefreshNumber       = 1;
  Command->ModeRegisterDefinition  = tmpmrd;

  /* Send the command */
  HAL_SDRAM_SendCommand(hsdram, Command, SDRAM_TIMEOUT);

  /* Step 6: Set the refresh rate counter */
  /* Set the device refresh rate */
  HAL_SDRAM_ProgramRefreshRate(hsdram, REFRESH_COUNT);
}

/**
  * @brief  IOE Low Level Initialization.
  */
void IOE_Init(void)
{
  //Dummy function called when initializing to stmpe811 to setup the i2c.
  //This is done with cubmx and is therfore not done here.
}

/**
  * @brief  IOE Low Level Interrupt configuration.
  */
void IOE_ITConfig(void)
{
  //Dummy function called when initializing to stmpe811 to setup interupt for the i2c.
  //The interupt is not used in our case, therefore nothing is done here.
}

/**
  * @brief  IOE Writes single data operation.
  * @param  Addr: I2C Address
  * @param  Reg: Reg Address
  * @param  Value: Data to be written
  */
void IOE_Write(uint8_t Addr, uint8_t Reg, uint8_t Value)
{
  I2C3_WriteData(Addr, Reg, Value);
}

/**
  * @brief  IOE Reads single data.
  * @param  Addr: I2C Address
  * @param  Reg: Reg Address
  * @retval The read data
  */
uint8_t IOE_Read(uint8_t Addr, uint8_t Reg)
{
  return I2C3_ReadData(Addr, Reg);
}

/**
  * @brief  IOE Reads multiple data.
  * @param  Addr: I2C Address
  * @param  Reg: Reg Address
  * @param  pBuffer: pointer to data buffer
  * @param  Length: length of the data
  * @retval 0 if no problems to read multiple data
  */
uint16_t IOE_ReadMultiple(uint8_t Addr, uint8_t Reg, uint8_t *pBuffer, uint16_t Length)
{
 return I2C3_ReadBuffer(Addr, Reg, pBuffer, Length);
}

/**
  * @brief  IOE Delay.
  * @param  Delay in ms
  */
void IOE_Delay(uint32_t Delay)
{
  HAL_Delay(Delay);
}

/**
  * @brief  Writes a value in a register of the device through BUS.
  * @param  Addr: Device address on BUS Bus.
  * @param  Reg: The target register address to write
  * @param  Value: The target register value to be written
  */
static void I2C3_WriteData(uint8_t Addr, uint8_t Reg, uint8_t Value)
{
  HAL_StatusTypeDef status = HAL_OK;

  status = HAL_I2C_Mem_Write(&hi2c3, Addr, (uint16_t)Reg, I2C_MEMADD_SIZE_8BIT, &Value, 1, I2c3Timeout);

  /* Check the communication status */
  if(status != HAL_OK)
  {
    /* Re-Initialize the BUS */
    //I2Cx_Error();
  }
}

/**
  * @brief  Reads a register of the device through BUS.
  * @param  Addr: Device address on BUS Bus.
  * @param  Reg: The target register address to write
  * @retval Data read at register address
  */
static uint8_t I2C3_ReadData(uint8_t Addr, uint8_t Reg)
{
  HAL_StatusTypeDef status = HAL_OK;
  uint8_t value = 0;

  status = HAL_I2C_Mem_Read(&hi2c3, Addr, Reg, I2C_MEMADD_SIZE_8BIT, &value, 1, I2c3Timeout);

  /* Check the communication status */
  if(status != HAL_OK)
  {
    /* Re-Initialize the BUS */
    //I2Cx_Error();

  }
  return value;
}

/**
  * @brief  Reads multiple data on the BUS.
  * @param  Addr: I2C Address
  * @param  Reg: Reg Address
  * @param  pBuffer: pointer to read data buffer
  * @param  Length: length of the data
  * @retval 0 if no problems to read multiple data
  */
static uint8_t I2C3_ReadBuffer(uint8_t Addr, uint8_t Reg, uint8_t *pBuffer, uint16_t Length)
{
  HAL_StatusTypeDef status = HAL_OK;

  status = HAL_I2C_Mem_Read(&hi2c3, Addr, (uint16_t)Reg, I2C_MEMADD_SIZE_8BIT, pBuffer, Length, I2c3Timeout);

  /* Check the communication status */
  if(status == HAL_OK)
  {
    return 0;
  }
  else
  {
    /* Re-Initialize the BUS */
    //I2Cx_Error();

    return 1;
  }
}

/**
  * @brief  Reads 4 bytes from device.
  * @param  ReadSize: Number of bytes to read (max 4 bytes)
  * @retval Value read on the SPI
  */
static uint32_t SPI5_Read(uint8_t ReadSize)
{
  HAL_StatusTypeDef status = HAL_OK;
  uint32_t readvalue;

  status = HAL_SPI_Receive(&hspi5, (uint8_t*) &readvalue, ReadSize, Spi5Timeout);

  /* Check the communication status */
  if(status != HAL_OK)
  {
    /* Re-Initialize the BUS */
    SPI5_Error();
  }

  return readvalue;
}

/**
  * @brief  Writes a byte to device.
  * @param  Value: value to be written
  */
static void SPI5_Write(uint16_t Value)
{
  HAL_StatusTypeDef status = HAL_OK;

  status = HAL_SPI_Transmit(&hspi5, (uint8_t*) &Value, 1, Spi5Timeout);

  /* Check the communication status */
  if(status != HAL_OK)
  {
    /* Re-Initialize the BUS */
    SPI5_Error();
  }
}

/**
  * @brief  SPI5 error treatment function.
  */
static void SPI5_Error(void)
{
  /* De-initialize the SPI communication BUS */
  //HAL_SPI_DeInit(&SpiHandle);

  /* Re- Initialize the SPI communication BUS */
  //SPIx_Init();
}

void LCD_IO_Init(void)
{
  /* Set or Reset the control line */
  HAL_GPIO_WritePin(GPIOC, GPIO_PIN_2, GPIO_PIN_RESET);
  HAL_GPIO_WritePin(GPIOC, GPIO_PIN_2, GPIO_PIN_SET);
}

/**
  * @brief  Writes register value.
  */
void LCD_IO_WriteData(uint16_t RegValue)
{
  /* Set WRX to send data */
  HAL_GPIO_WritePin(GPIOD, GPIO_PIN_13, GPIO_PIN_SET);

  /* Reset LCD control line(/CS) and Send data */
  HAL_GPIO_WritePin(GPIOC, GPIO_PIN_2, GPIO_PIN_RESET);
  SPI5_Write(RegValue);

  /* Deselect: Chip Select high */
  HAL_GPIO_WritePin(GPIOC, GPIO_PIN_2, GPIO_PIN_SET);
}

/**
  * @brief  Writes register address.
  */
void LCD_IO_WriteReg(uint8_t Reg)
{
  /* Reset WRX to send command */
  HAL_GPIO_WritePin(GPIOD, GPIO_PIN_13, GPIO_PIN_RESET);

  /* Reset LCD control line(/CS) and Send command */
  HAL_GPIO_WritePin(GPIOC, GPIO_PIN_2, GPIO_PIN_RESET);
  SPI5_Write(Reg);

  /* Deselect: Chip Select high */
  HAL_GPIO_WritePin(GPIOC, GPIO_PIN_2, GPIO_PIN_SET);
}

/**
  * @brief  Reads register value.
  * @param  RegValue Address of the register to read
  * @param  ReadSize Number of bytes to read
  * @retval Content of the register value
  */
uint32_t LCD_IO_ReadData(uint16_t RegValue, uint8_t ReadSize)
{
  uint32_t readvalue = 0;

  /* Select: Chip Select low */
  HAL_GPIO_WritePin(GPIOC, GPIO_PIN_2, GPIO_PIN_RESET);

  /* Reset WRX to send command */
  HAL_GPIO_WritePin(GPIOD, GPIO_PIN_13, GPIO_PIN_RESET);

  SPI5_Write(RegValue);

  readvalue = SPI5_Read(ReadSize);

  /* Set WRX to send data */
  HAL_GPIO_WritePin(GPIOD, GPIO_PIN_13, GPIO_PIN_SET);

  /* Deselect: Chip Select high */
  HAL_GPIO_WritePin(GPIOC, GPIO_PIN_2, GPIO_PIN_SET);

  return readvalue;
}

/**
  * @brief  Wait for loop in ms.
  * @param  Delay in ms.
  */
void LCD_Delay(uint32_t Delay)
{
  HAL_Delay(Delay);
}

/*Customised function callback*/

void HAL_UART_TxCpltCallback(UART_HandleTypeDef *huart)
{
   HAL_GPIO_TogglePin(GPIOG, GPIO_PIN_13);
}

void HAL_ADC_ConvHalfCpltCallback(ADC_HandleTypeDef* hadc) {
 // HAL_GPIO_WritePin(LD3_GPIO_Port, LD3_Pin, GPIO_PIN_SET);
}

// Called when buffer is completely filled
void HAL_ADC_ConvCpltCallback(ADC_HandleTypeDef* hadc) {
 // HAL_GPIO_WritePin(LD3_GPIO_Port, LD3_Pin, GPIO_PIN_RESET);
  NewBuffState=1;
}

//Complex division function
float32_t complexDiv_R(float32_t R1,float32_t I1,float32_t R2,float32_t I2){
	return (R1*R2+I1*I2)/(pow(R2,2)+pow(I2,2));
}

float32_t complexDiv_X(float32_t R1,float32_t I1,float32_t R2,float32_t I2){
	return (I1*R2+R1*I2)/(pow(R2,2)+pow(I2,2));
}

//FFT Function
void DoFFT(int frequency){
	int N_real;
	int N_imag;

	float32_t P_real;
	float32_t P_imag;
	float32_t Q_real;
	float32_t Q_imag;

	arm_rfft_fast_f32(&fft_handler, &fftin_buf_p, &out_buf_p, 0);
	arm_rfft_fast_f32(&fft_handler, &fftin_buf_q, &out_buf_q, 0);

	N_real=2*frequency-2;
	N_imag=2*frequency-1;

	P_real=out_buf_p[N_real];
	P_imag=out_buf_p[N_imag];
	Q_real=out_buf_q[N_real];
	Q_imag=out_buf_q[N_imag];

	if(frequency<31){
		Resistance[frequency]=complexDiv_R(P_real, P_imag,Q_real,Q_imag);
		Reactance[frequency]=complexDiv_X(P_real, P_imag,Q_real,Q_imag);
	}
}

//Float to string converter, taking place sprintf.

// reverses a string 'str' of length 'len'
void reverse(char *str, int len)
{
    int i=0, j=len-1, temp;
    while (i<j)
    {
        temp = str[i];
        str[i] = str[j];
        str[j] = temp;
        i++; j--;
    }
}

 // Converts a given integer x to string str[].  d is the number
 // of digits required in output. If d is more than the number
 // of digits in x, then 0s are added at the beginning.
//NPflag: negative or positive
int intToStr(int x, char str[], int d, int NPflag)
{
    int i = 0;
    while (x)
    {
        str[i++] = (x%10) + '0';
        x = x/10;
    }
    if(NPflag==0){
        str[i++] = '-';
    }
    // If number of digits required is more, then
    // add 0s at the beginning
    while (i < d)
        str[i++] = '0';

    reverse(str, i);
    str[i] = ' ';
    return i;
}

// Converts a floating point number to string.
void ftoa(float n, char *res, int afterpoint)
{
	float m;
	int flag;
	int ipart;
    // Extract integer part
    if(n<0){
    	m = -n;
    	ipart = -(int)n;
    	flag=0;
    }//Negarive integer part
    else{
    	m=n;
        ipart = (int)n;
        flag=1;
    }//Positive integer part
    // Extract floating part
    float fpart = m - (float)ipart;

    // convert integer part to string
    int i = intToStr(ipart, res, 0, flag);

    // check for display option after point
    if (afterpoint != 0)
    {
        res[i] = '.';  // add dot

        // Get the value of fraction part upto given no.
        // of points after dot. The third parameter is needed
        // to handle cases like 233.007
        fpart = fpart * pow(10, afterpoint);

        intToStr((int)fpart, res + i + 1, afterpoint,1);
    }
}

/* USER CODE END 4 */

__weak void TouchGFX_Task(void *argument)
{
  for(;;)
  {
    osDelay(1);
  }
}

void ImpedanceCalculator(void *argument)
{
  /* USER CODE BEGIN ImpedanceCalculator */
	int ac_get;

	osMessageQueueGet(CallMeasurementHandle,&ac_get, NULL, osWaitForever);
	if(ac_get==0){
        //osThreadSuspend(TemperatureContHandle);
        osThreadSuspend(AccuatorHandle);
        osThreadSuspend(PQReaderHandle);
		}
	if(ac_get==1){
       // osThreadResume(TemperatureContHandle);
        osThreadResume(AccuatorHandle);
        osThreadResume(PQReaderHandle);
	}

	int n;
		/* Infinite loop */
		  while(1)
		  {

			  HAL_ADC_Start_DMA(&hadc1, (uint32_t*)adc_buf_p, ADC_BUF_LEN_P); //Pressure sensing
			  HAL_ADC_Start_DMA(&hadc2, (uint32_t*)adc_buf_q, ADC_BUF_LEN_Q); //Flow rate sensing

			  for (n=0;n<2048;n=n+1){

				  fftin_buf_p[n]=((float32_t)adc_buf_p[n]*3/4096/3.3-0.5)*pow(((float32_t)adc_buf_p[n]*3/4096/1.32-1.25),2)*525;//Pressure sensor conversion - Pa
				  fftin_buf_q[n]=(((float32_t)adc_buf_q[n]*3/4096/3.3-0.5)*pow(((float32_t)adc_buf_p[n]*3/4096/1.32-1.25),2)*525)*2.083/98.066;// Flow rate conversion - L/s
			    }

			  if(NewBuffState==1){
				 DoFFT(Freq);
				 Freq++;
				 osMessageQueuePut(ADCstateHandle, &NewBuffState, 0, 200);
				 NewBuffState=0;
			  }
		  }
	//}

  /* USER CODE END ImpedanceCalculator */
}

void TempControl(void *argument)
{
  /* USER CODE BEGIN TempControl */
  //int ac2=0;
  /* Infinite loop */
  for(;;)
  {
	  //if(xQueueReceive(messageQ, &ac2, 0)== pdTRUE){
	    HAL_ADC_Start(&hadc3);
	  // Poll ADC1 Perihperal & TimeOut = 1mSec
	    HAL_ADC_PollForConversion(&hadc3, 1);
	    Temp_Vdigital=HAL_ADC_GetValue(&hadc3);

	    Temp_Vanalogue=(float)Temp_Vdigital*3/4096;
	    Temp=(Temp_Vanalogue-0.5)/0.01-16;

	    if(Temp<=35){
	    	HAL_GPIO_WritePin(GPIOA, GPIO_PIN_1, GPIO_PIN_SET);
	    }
	    else
	    	HAL_GPIO_WritePin(GPIOA, GPIO_PIN_1, GPIO_PIN_RESET);

	    osDelay(500);
      }
  //}
  /* USER CODE END TempControl */
}

void StartActuating(void *argument)
{
  /* USER CODE BEGIN StartActuating */

	 //int ac3=0;
	// if(xQueueReceive(messageQ, &ac3, 0)== pdTRUE){
	  //-----------Frequency Sweeping function----------------//
		  //Get ADC state from task1.
		  uint8_t buffer_get;

	  /* Infinite loop */

	  while(1){

		  if(FreqSweep<=30){

		      osMessageQueueGet(ADCstateHandle,&buffer_get, 0, osWaitForever);

			  if(buffer_get==1){
				            htim2.Instance->CCR1=htim2.Instance->ARR * 0.50;
			 	        	FreqSweepConverter=1000/FreqSweep+1;
			 				htim2.Instance->PSC=FreqSweepConverter;
			 				FreqSweep++;
			 				osMessageQueuePut(ProgressBarHandle, &FreqSweep, 0, 20);
		      }
	       }

		  if(FreqSweep==31){
			  FreqSweep=0;
//			  HAL_TIM_PWM_Stop(&htim4, TIM_CHANNEL_2);
			  htim2.Instance->CCR1=htim2.Instance->ARR +1;
			  osThreadSuspend(PQReaderHandle);
			  osThreadSuspend(TemperatureContHandle);
			 // osThreadTerminate(AccuatorHandle);
	      }
	  }
	//}
  /* USER CODE END StartActuating */
}

void SaveData(void *argument)
{
  /* USER CODE BEGIN SaveData */
	int i,m;
	  char string1[8];
	  char string2[8];
	  char IntroText1[]="Patient:\n Gender:\n Age:\n Height:\n Weight\n ";
	  char IntroText2[]="Respiratory Resistance from 5Hz to 30Hz:\n";
	  char IntroText3[]="Respiratory Reactance from 5Hz to 30Hz:\n";
	  char IntroText4[]="Measuring Date:\n";
	  int Flag;
	  int endFlag=0;
	  osMessageQueueGet(SaveDataCheckHandle,&Flag,0,osWaitForever);
	  if(Flag==1){
		  HAL_UART_Transmit_IT(&huart1, (uint8_t*)IntroText1, sizeof(IntroText1));
		  HAL_UART_Transmit_IT(&huart1, (uint8_t*)IntroText2, sizeof(IntroText2));
		  for(i=5;i<31;i++){
			ftoa(Resistance[i], string1, 3);
			HAL_UART_Transmit_IT(&huart1, (uint8_t*)string1, sizeof(string1)); //add UART IT callback.
		  }
		  HAL_UART_Transmit_IT(&huart1, (uint8_t*)IntroText3, sizeof(IntroText3));
		  for(m=5;m<31;m++){
			ftoa(Reactance[m], string2, 3);
			HAL_UART_Transmit_IT(&huart1, (uint8_t*)string2, sizeof(string2)); //add UART IT callback.
		  }
		  HAL_UART_Transmit_IT(&huart1, (uint8_t*)IntroText4, sizeof(IntroText4));
		  osMessageQueuePut(SaveDataEndHandle, &endFlag, 0, 1000);
	  }
//	  /* Infinite loop */
//	  for(;;)
//	  {
//	    osDelay(1);
//	  }
  /* USER CODE END SaveData */
}

 /**
  * @brief  Period elapsed callback in non blocking mode
  * @note   This function is called  when TIM6 interrupt took place, inside
  * HAL_TIM_IRQHandler(). It makes a direct call to HAL_IncTick() to increment
  * a global variable "uwTick" used as application time base.
  * @param  htim : TIM handle
  * @retval None
  */
void HAL_TIM_PeriodElapsedCallback(TIM_HandleTypeDef *htim)
{
  if (htim->Instance == TIM6) {
    HAL_IncTick();
  }
}

void Error_Handler(void)
{
}

/************************ (C) COPYRIGHT STMicroelectronics *****END OF FILE****/
